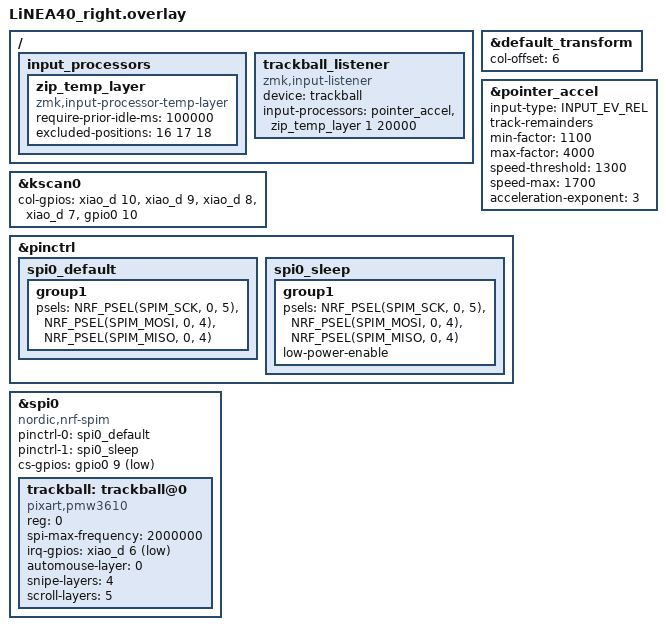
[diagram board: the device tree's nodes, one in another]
#include "LiNEA40.dtsi"
#include <zephyr/dt-bindings/input/input-event-codes.h>
#include <behaviors/input_gestures_accel.dtsi>

&default_transform {
    col-offset = <6>;
};

&kscan0 {
    col-gpios
        = <&xiao_d 10 GPIO_ACTIVE_HIGH> //col0-D10
        , <&xiao_d 9 GPIO_ACTIVE_HIGH>  //col1-D9
        , <&xiao_d 8 GPIO_ACTIVE_HIGH>  //col2-D8
        , <&xiao_d 7 GPIO_ACTIVE_HIGH>  //col3-D7
        , <&gpio0 10 GPIO_ACTIVE_HIGH>  //col4-NFC2
        ;
};

/* トラックボールのポインタ加速。カーソルを速く動かすほど移動量が
   大きくなる。値は千分率(1000=等倍)。cpi=400 前提の counts/sec。 */

&pointer_accel {
    input-type = <INPUT_EV_REL>;
    track-remainders;            // 端数を蓄積して精度低下を防ぐ

    min-factor = <1100>;         // ゆっくり動かした時は等倍(1.0x)
    max-factor = <4000>;         // 速く動かした時は最大4倍まで加速
    speed-threshold = <1300>;    // これ未満の速度では等倍(1.0x)
    speed-max = <1700>;          // これ以上の速度で最大倍率に到達
    acceleration-exponent = <3>; // 1=線形 / 2=二次関数的 / 3=三次関数的カーブ
};

/ {
    /* 1. input_processors の実体をここで定義 */
    input_processors {
        zip_temp_layer: zip_temp_layer {
            compatible = "zmk,input-processor-temp-layer";
            #input-processor-cells = <2>;
            require-prior-idle-ms = <100000>;
            /* クリックキーなどを押している間に解除されないようにする設定 */
            excluded-positions = <16 17 18>; 
        };
    };

    /* 2. トラックボールの動作リスナー設定 */
    trackball_listener {
        compatible = "zmk,input-listener";
        device = <&trackball>;
        status = "okay";

        /* ここで定義した zip_temp_layer を呼び出す */
        /* 第1引数: マウスレイヤー番号(1)、第2引数: 解除までの時間(ms) */
        input-processors = <&pointer_accel>, <&zip_temp_layer 1 20000>;
    };
};

&pinctrl {
    spi0_default: spi0_default {
        group1 {
            psels = <NRF_PSEL(SPIM_SCK, 0, 5)>   // SCLK-D5
                  , <NRF_PSEL(SPIM_MOSI, 0, 4)>  // SDIO-D4
                  , <NRF_PSEL(SPIM_MISO, 0, 4)>  // SDIO-D4
                  ;
        };
    };

    spi0_sleep: spi0_sleep {
        group1 {
            psels = <NRF_PSEL(SPIM_SCK, 0, 5)>   // SCLK-D5
                  , <NRF_PSEL(SPIM_MOSI, 0, 4)>  // SDIO-D4
                  , <NRF_PSEL(SPIM_MISO, 0, 4)>  // SDIO-D4
                  ;
            low-power-enable;
        };
    };
};

&spi0 {
    status = "okay";
    compatible = "nordic,nrf-spim";
    pinctrl-0 = <&spi0_default>;
    pinctrl-1 = <&spi0_sleep>;
    pinctrl-names = "default", "sleep";
    cs-gpios = <&gpio0 9 GPIO_ACTIVE_LOW>; //NCS-NFC1

    trackball: trackball@0 {
        status = "okay";
        compatible = "pixart,pmw3610";
        reg = <0>;
        spi-max-frequency = <2000000>;
        irq-gpios = <&xiao_d 6 (GPIO_ACTIVE_LOW | GPIO_PULL_UP)>; //MOT-D6
        
        /* ドライバ標準の自動レイヤーは 0(無効) にして zip_temp_layer に任せる */
        automouse-layer = <0>; 
        snipe-layers = <4>;
        scroll-layers = <5>;
    };
};
